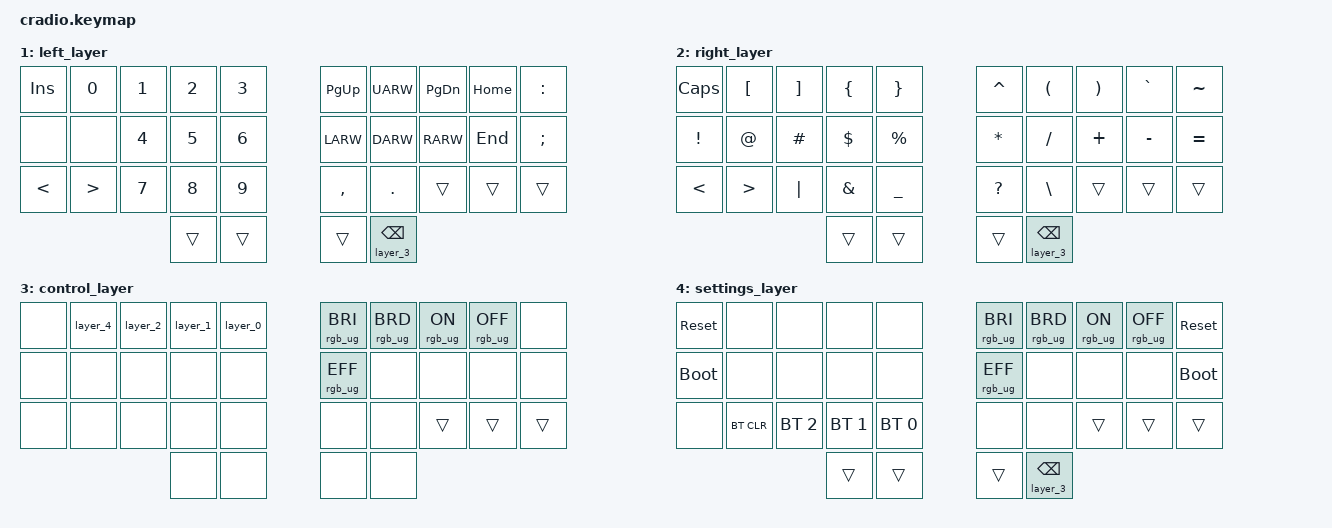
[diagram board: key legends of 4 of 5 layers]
// Copyright (c) 2022 The ZMK Contributors
// SPDX-License-Identifier: MIT

#include <behaviors.dtsi>
#include <dt-bindings/zmk/keys.h>
#include <dt-bindings/zmk/outputs.h>
#include <dt-bindings/zmk/bt.h>
#include <dt-bindings/led/led.h>
#include <dt-bindings/zmk/rgb.h>
#include "34keys.h"


// Home row mods macro
#define HRML(k1,k2,k3,k4) &ht LSHFT k1  &ht LGUI k2  &ht LCTRL k3  &ht LALT k4
#define HRMR(k1,k2,k3,k4) &ht RALT k1  &ht RCTRL k2  &ht RGUI k3  &ht RSHFT k4

/ {
    chosen {
        zmk,underglow = &led_strip;
    };
};

/ {
    behaviors {
        ht: hold_tap {
            label = "hold_tap";
            compatible = "zmk,behavior-hold-tap";
            #binding-cells = <2>;
            flavor = "tap-preferred";
            tapping-term-ms = <220>;
            quick-tap-ms = <150>;
            global-quick-tap;
            bindings = <&kp>, <&kp>;
	l_kp: l_kp {
       		compatible = "zmk,behavior-hold-tap";
        	label = "LAYER_MACRO";
        	#binding-cells = <2>;
        	flavor = "hold-preferred";
        	tapping-term-ms = <200>;
        	bindings = <&layer_3>, <&kp>;  // &mo on hold, &macro on tap
    };
        };
    };
};  
#define COMBO(name, keypress, keypos) \
combo_##name {                        \
	timeout-ms = <2000>;                \
	bindings = <keypress>;            \
	key-positions = <keypos>;         \
};

/ {
	combos {
		compatible = "zmk,combos";
		// invoke macros
		COMBO(layer_0,  &layer_0,   31  4)
		COMBO(layer_1,  &layer_1,   31  3)
		COMBO(layer_2,  &layer_2,   31  2)
		COMBO(layer_4,  &layer_4,   31  1)

	};
};

/ {	
    macros {
            ZMK_MACRO(layer_0,
    	    wait-ms = <0>;
    	    tap-ms = <0>;
            bindings
                = <&macro_press &to 0>
                , <&macro_tap &rgb_ug RGB_COLOR_HSB(128,100,100)>
                , <&macro_pause_for_release>
                , <&macro_release &to 0>
                , <&macro_tap &rgb_ug RGB_COLOR_HSB(210,100,100)>;
		)
		
	    ZMK_MACRO(layer_1,
	    wait-ms = <0>;
    	    tap-ms = <0>;
            bindings
                = <&macro_press &to 1>
                , <&macro_tap &rgb_ug RGB_COLOR_HSB(128,100,100)>
                , <&macro_pause_for_release>
                , <&macro_release &to 1>
                , <&macro_tap &rgb_ug RGB_COLOR_HSB(305,100,100)>;
		)
		
	    ZMK_MACRO(layer_2,
	    wait-ms = <0>;
    	    tap-ms = <0>;
            bindings
                = <&macro_press &to 2>
                , <&macro_tap &rgb_ug RGB_COLOR_HSB(128,100,100)>
                , <&macro_pause_for_release>
                , <&macro_release &to 2>
                , <&macro_tap &rgb_ug RGB_COLOR_HSB(55,90,55)>;
		)
		
	    ZMK_MACRO(layer_3,
	    wait-ms = <0>;
    	    tap-ms = <0>;
            bindings 
		= <&macro_press &to 3>
                , <&macro_tap &rgb_ug RGB_COLOR_HSB(128,100,100)>
                , <&macro_pause_for_release>
                , <&macro_release &to 3>
                , <&macro_tap &rgb_ug RGB_COLOR_HSB(0,0,100)>;
		)
	    ZMK_MACRO(layer_4,
	    wait-ms = <0>;
    	    tap-ms = <0>;
            bindings 
		= <&macro_press &to 4>
                , <&macro_tap &rgb_ug RGB_COLOR_HSB(128,100,100)>
                , <&macro_pause_for_release>
                , <&macro_release &to 4>
                , <&macro_tap &rgb_ug RGB_COLOR_HSB(0,100,100)>;
		)
    };
};

&caps_word {
    continue-list = <UNDERSCORE MINUS>;
};

&mt {
    tapping-term-ms = <400>;
};

/ {
    keymap {
        compatible = "zmk,keymap";
        default_layer {
            bindings = <
        //╭──────────┬──────────┬──────────┬──────────┬──────────╮   ╭──────────┬──────────┬──────────┬──────────┬──────────╮
        //│  Q       │  W       │  E       │  R       │  T       │   │  Y       │  U       │  I       │  O       │  P       │
            &kp Q      &kp W      &kp E      &kp R      &kp T          &kp Y      &kp U      &kp I      &kp O      &kp P
        //├──────────┼──────────┼──────────┼──────────┼──────────┤   ├──────────┼──────────┼──────────┼──────────┼──────────┤
        //│  A       │  S       │  D       │  F       │  G       │   │  H       │  J       │  K       │  L       │ ' "      │
            HRML(A,        S,         D,         F)     &kp G          &kp H      HRMR(J,        K,         L,        SQT)
        //├──────────┼──────────┼──────────┼──────────┼──────────┤   ├──────────┼──────────┼──────────┼──────────┼──────────┤
        //│  Z       │  X       │  C       │  V       │  B       │   │  N       │  M       │ ESC      │ NONE     │ DELETE   │
            &kp Z      &kp X      &kp C      &kp V      &kp B          &kp N      &kp M      &kp ESC    &none      &kp DEL
        //╰──────────┴──────────┴──────────┼──────────┼──────────┤   ├──────────┼──────────┼──────────┴──────────┴──────────╯
                                             &kp TAB    &kp ENTER      &kp SPACE  &l_kp 0 BKSP
        //                                 ╰──────────┴──────────╯   ╰──────────┴──────────╯
            >;
        };

        left_layer {
            bindings = <
        //╭──────────┬──────────┬──────────┬──────────┬──────────╮   ╭──────────┬──────────┬──────────┬──────────┬──────────╮
        //│ INSERT   │  0       │  1       │  2       │  3       │   │ PAGE UP  │ UP       │ PAGE DN  │ HOME     │  :       │
            &kp INS    &kp N0     &kp N1     &kp N2     &kp N3         &kp PG_UP  &kp UARW  &kp PG_DN  &kp HOME   &kp COLON
        //├──────────┼──────────┼──────────┼──────────┼──────────┤   ├──────────┼──────────┼──────────┼──────────┼──────────┤
        //│          │          │  4       │  5       │  6       │   │ LEFT     │ DOWN     │ RIGHT    │ END      │  ;       │
            &none      &none      &kp N4     &kp N5     &kp N6         &kp LARW   &kp DARW   &kp RARW   &kp END    &kp SEMI
        //├──────────┼──────────┼──────────┼──────────┼──────────┤   ├──────────┼──────────┼──────────┼──────────┼──────────┤
        //│ <        │ >        │  7       │  8       │  9       │   │ ,        │ .        │          │          │          │
            &kp LT     &kp GT     &kp N7     &kp N8     &kp N9         &kp COMMA  &kp DOT    &trans     &trans     &trans 
        //╰──────────┴──────────┴──────────┼──────────┼──────────┤   ├──────────┼──────────┼──────────┴──────────┴──────────╯
                                             &trans     &trans         &trans     &l_kp 0 BKSP
        //                                 ╰──────────┴──────────╯   ╰──────────┴──────────╯
            >;
        };

        right_layer {
            bindings = <
        //╭──────────┬──────────┬──────────┬──────────┬──────────╮   ╭──────────┬──────────┬──────────┬──────────┬──────────╮
        //│ CAPSLOCK │  [       │  ]       │  {       │ }        │   │  ^       │  (       │  )       │  `       │  ~       │
            &kp CAPS   &kp LBKT   &kp RBKT   &kp LBRC   &kp RBRC       &kp CARET  &kp LPAR   &kp RPAR   &kp GRAVE  &kp TILDE
        //├──────────┼──────────┼──────────┼──────────┼──────────┤   ├──────────┼──────────┼──────────┼──────────┼──────────┤
        //│  !       │  @       │  #       │  $       │  %       │   │  *       │  /       │  +       │  -       │  =       │
            &kp EXCL   &kp AT     &kp HASH   &kp DLLR   &kp PRCNT      &kp ASTRK  &kp FSLH   &kp PLUS   &kp MINUS  &kp EQUAL
        //├──────────┼──────────┼──────────┼──────────┼──────────┤   ├──────────┼──────────┼──────────┼──────────┼──────────┤
        //│  <       │  >       │  |       │  &       │  _       │   │  ?       │  \       │          │          │          │
            &kp LT     &kp GT     &kp PIPE   &kp AMPS   &kp UNDER      &kp QMARK  &kp BSLH   &trans     &trans     &trans
        //╰──────────┴──────────┴──────────┼──────────┼──────────┤   ├──────────┼──────────┼──────────┴──────────┴──────────╯
                                             &trans     &trans         &trans     &l_kp 0 BKSP
        //                                 ╰──────────┴──────────╯   ╰──────────┴──────────╯
            >;
        };

        control_layer {
            bindings = <
        //╭──────────┬──────────┬──────────┬──────────┬──────────╮   ╭──────────┬──────────┬──────────┬──────────┬──────────╮
        //│          │          │          │          │          │   │   LED +  │  LED -   │  LED ON  │ LED OFF  │          │
            &none      &layer_4     &layer_2      &layer_1     &layer_0       &rgb_ug RGB_BRI &rgb_ug RGB_BRD &rgb_ug RGB_ON &rgb_ug RGB_OFF &none
        //├──────────┼──────────┼──────────┼──────────┼──────────┤   ├──────────┼──────────┼──────────┼──────────┼──────────┤
        //│          │          │          │          │          │   │ LED EFF  │          │          │          │          │
            &none      &none      &none      &none      &none       &rgb_ug RGB_EFF &none    &none      &none      &none
        //├──────────┼──────────┼──────────┼──────────┼──────────┤   ├──────────┼──────────┼──────────┼──────────┼──────────┤
        //│          │          │          │          │          |   |          │          │          │          │          │
            &none      &none      &none      &none      &none          &none      &none      &trans     &trans     &trans   
        //╰──────────┴──────────┴──────────┼──────────┼──────────┤   ├──────────┼──────────┼──────────┴──────────┴──────────╯
                                             &none      &none          &none     &none
        //                                 ╰──────────┴──────────╯   ╰──────────┴──────────╯
            >;
        };
	
	settings_layer {
            bindings = <
        //╭──────────┬──────────┬──────────┬──────────┬──────────╮   ╭──────────┬──────────┬──────────┬──────────┬──────────╮
        //│ RESET    │          │          │          │          │   │   LED +  │  LED -   │  LED ON  │ LED OFF  │  RESET   │
            &sys_reset     &none      &none      &none      &none       &rgb_ug RGB_BRI &rgb_ug RGB_BRD &rgb_ug RGB_ON &rgb_ug RGB_OFF &sys_reset
        //├──────────┼──────────┼──────────┼──────────┼──────────┤   ├──────────┼──────────┼──────────┼──────────┼──────────┤
        //│BOOTLOADER│          │          │          │          │   │ LED EFF  │          │          │          │BOOTLOADER│
          &bootloader  &none      &none      &none      &none       &rgb_ug RGB_EFF &none    &none      &none      &bootloader
        //├──────────┼──────────┼──────────┼──────────┼──────────┤   ├──────────┼──────────┼──────────┼──────────┼──────────┤
        //│          │ CLEAR BT │ PROFILE 2│ PROFILE 1│ PROFILE 0|   |          │          │          │          │          │
            &none    &bt BT_CLR &bt BT_SEL 2 &bt BT_SEL 1 &bt BT_SEL 0 &none        &none    &trans     &trans     &trans   
        //╰──────────┴──────────┴──────────┼──────────┼──────────┤   ├──────────┼──────────┼──────────┴──────────┴──────────╯
                                             &trans     &trans         &trans     &l_kp 0 BKSP
        //                                 ╰──────────┴──────────╯   ╰──────────┴──────────╯
            >;
        };
    };
};
